# DECODER0_MSVDX_VEC_AVS register map
Vendor: Texas Instruments
Peripheral module from a debugger description file (folder J7ES).
Registers are 32-bit, read-write, reset 0x0 unless marked. A register's access mark holds for its fields unless they carry their own. Offsets are as the file gives them; lines under a group give offsets from that group; [hi:lo] are bit positions; {n}, {i} and the like mark numbered series; 'fields as' and 'values as' point back to an identical list; <NAME> marks a mode.

## DECODER0_MSVDX_VEC_AVS
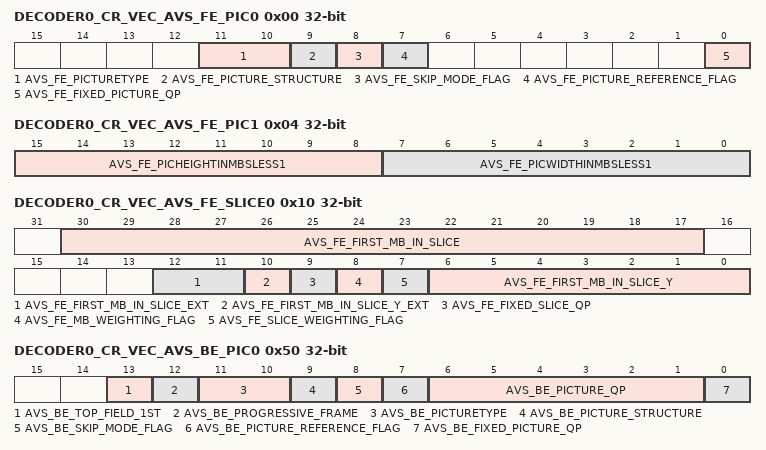
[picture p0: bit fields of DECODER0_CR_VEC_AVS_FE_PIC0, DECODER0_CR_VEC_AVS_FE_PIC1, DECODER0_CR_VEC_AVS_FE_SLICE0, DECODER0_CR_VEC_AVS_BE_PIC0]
0x00 DECODER0_CR_VEC_AVS_FE_PIC0 — Required parameter set for front end parsing
  [11:10] AVS_FE_PICTURETYPE — Indicates the current picture type -
  [9] AVS_FE_PICTURE_STRUCTURE — '0' indicates that the coded data of the two fields of current picture will
  [8] AVS_FE_SKIP_MODE_FLAG — '0' indicates the macroblock skip mode is derived from mb_type
  [7] AVS_FE_PICTURE_REFERENCE_FLAG — '0' means that every macroblock specifies the reference pictures to be used
  [0] AVS_FE_FIXED_PICTURE_QP — '0' indicates the quantization parameter may change
0x04 DECODER0_CR_VEC_AVS_FE_PIC1 — Picture parameter set 1 for AVS
  [15:8] AVS_FE_PICHEIGHTINMBSLESS1 — Current picture height in macroblocks less 1
  [7:0] AVS_FE_PICWIDTHINMBSLESS1 — Current picture width in macroblocks less 1
0x08 DECODER0_CR_VEC_AVS_FE_PIC2 — Picture parameter set 2 for AVS
  [15:0] AVS_FE_PICSIZEINMBSLESS1 — Current picture size in macroblocks less 1
0x10 DECODER0_CR_VEC_AVS_FE_SLICE0 — Slice parameter set 3 for AVS
  [30:17] AVS_FE_FIRST_MB_IN_SLICE
  [12:11] AVS_FE_FIRST_MB_IN_SLICE_EXT — Extension field for AVS_FE_FIRST_MB_IN_SLICE for 4k x 4k support
  [10] AVS_FE_FIRST_MB_IN_SLICE_Y_EXT — Extension field for AVS_FE_FIRST_MB_IN_SLICE_Y for 4k x 4k support
  [9] AVS_FE_FIXED_SLICE_QP — '0' means that the quantization parameter may change
  [8] AVS_FE_MB_WEIGHTING_FLAG — '0' indicates that all inter coded macroblocks shall use weighted
  [7] AVS_FE_SLICE_WEIGHTING_FLAG — '0' indicates that weighted prediction shall not be applied to inter prediction
  [6:0] AVS_FE_FIRST_MB_IN_SLICE_Y — Indicates the starting Y address for the first macroblock in the slice.
0x50 DECODER0_CR_VEC_AVS_BE_PIC0 — Required parameter set for back end parsing
  [13] AVS_BE_TOP_FIELD_1ST — '0' indicates that the bottom field is first
  [12] AVS_BE_PROGRESSIVE_FRAME — '0' indicates that the 2 fields are interlaced fields
  [11:10] AVS_BE_PICTURETYPE — Indicates the current picture type -
  [9] AVS_BE_PICTURE_STRUCTURE — '0' indicates that the coded data of the two fields of current picture will
  [8] AVS_BE_SKIP_MODE_FLAG — '0' indicates the macroblock skip mode is derived from mb_type
  [7] AVS_BE_PICTURE_REFERENCE_FLAG — '0' means that every macroblock specifies the reference pictures to be used
  [6:1] AVS_BE_PICTURE_QP — Picture QP value to be used if AVS_BE_FIXED_PICTURE_QP is set to '1'
  [0] AVS_BE_FIXED_PICTURE_QP — '0' indicates the quantization parameter may change
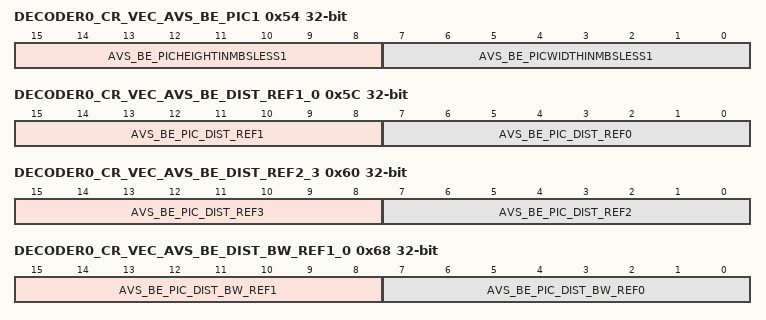
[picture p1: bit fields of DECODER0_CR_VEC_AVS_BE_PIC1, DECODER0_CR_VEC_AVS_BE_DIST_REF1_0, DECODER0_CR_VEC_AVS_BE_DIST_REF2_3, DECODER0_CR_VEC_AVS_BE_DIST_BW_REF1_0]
0x54 DECODER0_CR_VEC_AVS_BE_PIC1
  [15:8] AVS_BE_PICHEIGHTINMBSLESS1 — Current picture height in macroblocks less 1
  [7:0] AVS_BE_PICWIDTHINMBSLESS1 — Current picture width in macroblocks less 1
0x58 DECODER0_CR_VEC_AVS_BE_PIC2
  [15:0] AVS_BE_PICSIZEINMBSLESS1 — Picture size in macroblocks less 1
0x5C DECODER0_CR_VEC_AVS_BE_DIST_REF1_0
  [15:8] AVS_BE_PIC_DIST_REF1 — picture_distance parameter for the 2nd most recently decoded field.
  [7:0] AVS_BE_PIC_DIST_REF0 — picture_distance parameter for the most recently decoded field.
0x60 DECODER0_CR_VEC_AVS_BE_DIST_REF2_3
  [15:8] AVS_BE_PIC_DIST_REF3 — picture_distance parameter for the 4th most recently decoded field.
  [7:0] AVS_BE_PIC_DIST_REF2 — picture_distance parameter for the 3rd most recently decoded field.
0x64 DECODER0_CR_VEC_AVS_BE_DIST_CURR
  [7:0] AVS_BE_PIC_DIST_CURR — Picture_distance parameter for the current picture
0x68 DECODER0_CR_VEC_AVS_BE_DIST_BW_REF1_0 — Indices of the 4 possible reference pictures of the backward reference picture
  [15:8] AVS_BE_PIC_DIST_BW_REF1 — A stored version of PIC_DIST_REF1 as it was when the backward reference picture [last I/P picture] was decoded.
  [7:0] AVS_BE_PIC_DIST_BW_REF0 — A stored version of PIC_DIST_REF0 as it was when the backward reference picture [last I/P picture] was decoded.
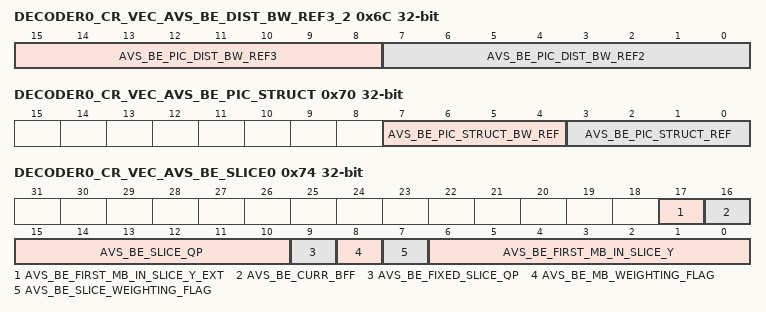
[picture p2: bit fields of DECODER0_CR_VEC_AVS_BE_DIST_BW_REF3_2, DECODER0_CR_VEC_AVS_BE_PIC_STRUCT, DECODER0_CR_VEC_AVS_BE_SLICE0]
0x6C DECODER0_CR_VEC_AVS_BE_DIST_BW_REF3_2
  [15:8] AVS_BE_PIC_DIST_BW_REF3 — A stored version of PIC_DIST_REF3 as it was when the backward reference picture [last I/P picture] was decoded.
  [7:0] AVS_BE_PIC_DIST_BW_REF2 — A stored version of PIC_DIST_REF2 as it was when the backward reference picture [last I/P picture] was decoded.
0x70 DECODER0_CR_VEC_AVS_BE_PIC_STRUCT
  [7:4] AVS_BE_PIC_STRUCT_BW_REF — A stored version of PIC_STRUCT_REF as it was when the backward reference picture [last I/P picture] was decoded.
  [3:0] AVS_BE_PIC_STRUCT_REF — picture_structure parameter for the 1st, 2nd, 3rd and 4th most recently decoded fields.
0x74 DECODER0_CR_VEC_AVS_BE_SLICE0 — Slice level parameters.
  [17] AVS_BE_FIRST_MB_IN_SLICE_Y_EXT — Extension field for AVS_BE_FIRST_MB_IN_SLICE_Y for 4k x 4k support
  [16] AVS_BE_CURR_BFF — '0' indicates that the current field is top
  [15:10] AVS_BE_SLICE_QP — Slice QP value to be used if AVS_BE_FIXED_SLICE_QP is set to '1'
  [9] AVS_BE_FIXED_SLICE_QP — '0' means that the quantization parameter may change
  [8] AVS_BE_MB_WEIGHTING_FLAG — '0' indicates that all inter coded macroblocks shall use weighted
  [7] AVS_BE_SLICE_WEIGHTING_FLAG — '0' indicates that weighted prediction shall not be applied to inter prediction
  [6:0] AVS_BE_FIRST_MB_IN_SLICE_Y — FIrst mblk in slice Y address
0x78 DECODER0_CR_VEC_AVS_BE_SLICE1 — Back End AVS slice-level parameters (from Slice Header).
  [1:0] AVS_BE_SLICE_FIELD_TYPE — SLICE_FIELD_TYPE of the Operating Mode Command
0xEC DECODER0_CR_VEC_AVS_BE_BASE_ADDR_CUR_PIC — Back End AVS base address for the macroblock parameters to be stored for the current picture
  [31:12] AVS_CURRPIC_PARAMS_BASE_ADDRESS
0xF8 DECODER0_CR_VEC_AVS_BE_BASE_ADDR_COL_PIC — Back End AVS base address to read the macroblock parameters for the colocated picture. This address can change per slice
  [31:12] AVS_COL_PIC_PARAMS_BASE_ADDRESS — Parameters base address for colocated picture
